AUTOSAR XML (schema 4-0-3)
standard types defined: Boolean, UInt16, UInt32
package /AUTOSAR_Platform/DataConstrs
  range DC_Boolean: raw 0..1
  range DC_UInt16: raw 0..65535
package /PATAC/MSM/ComponentTypes
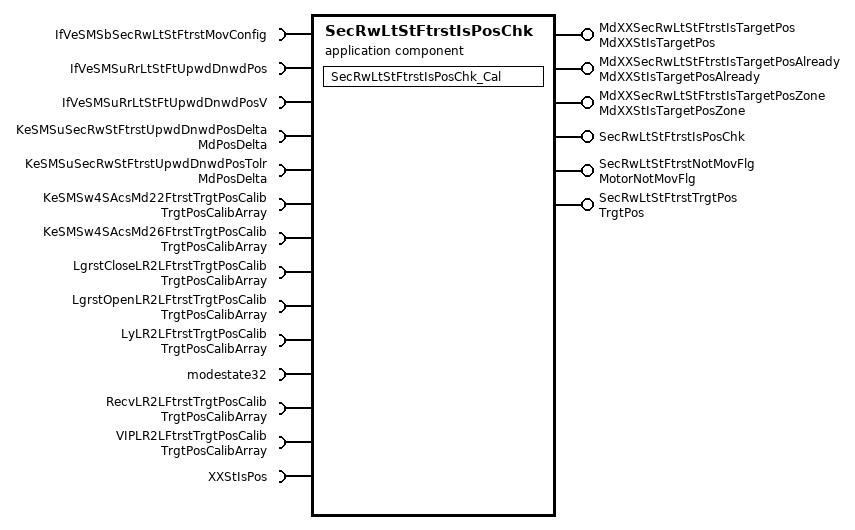
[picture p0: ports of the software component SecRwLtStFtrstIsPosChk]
  application sw component type SecRwLtStFtrstIsPosChk
    6 x provide port:
      MdXXSecRwLtStFtrstIsTargetPos: nonqueued-sender-com-spec=data-element=MdXXStIsTargetPos/Val, provided-interface=MdXXStIsTargetPos
      MdXXSecRwLtStFtrstIsTargetPosAlready: nonqueued-sender-com-spec=data-element=MdXXStIsTargetPosAlready/Val, provided-interface=MdXXStIsTargetPosAlready
      MdXXSecRwLtStFtrstIsTargetPosZone: nonqueued-sender-com-spec=data-element=MdXXStIsTargetPosZone/Val, provided-interface=MdXXStIsTargetPosZone
      SecRwLtStFtrstIsPosChk: server-com-spec{operation=Cal, queue-length=1}, provided-interface=SecRwLtStFtrstIsPosChk
      SecRwLtStFtrstNotMovFlg: nonqueued-sender-com-spec{data-element=MotorNotMovFlg/Val, init-value=0}, provided-interface=MotorNotMovFlg
      SecRwLtStFtrstTrgtPos: nonqueued-sender-com-spec{data-element=TrgtPos/Val, init-value=4095}, provided-interface=TrgtPos
    14 x require port:
      IfVeSMSbSecRwLtStFtrstMovConfig: nonqueued-receiver-com-spec{data-element=IfVeSMSbSecRwLtStFtrstMovConfig/Val, filter=data-filter-type=ALWAYS, init-value=0}, required-interface=IfVeSMSbSecRwLtStFtrstMovConfig
      IfVeSMSuRrLtStFtUpwdDnwdPos: nonqueued-receiver-com-spec{data-element=IfVeSMSuRrLtStFtUpwdDnwdPos/Val, filter=data-filter-type=ALWAYS, init-value=0}, required-interface=IfVeSMSuRrLtStFtUpwdDnwdPos
      IfVeSMSuRrLtStFtUpwdDnwdPosV: nonqueued-receiver-com-spec{data-element=IfVeSMSuRrLtStFtUpwdDnwdPosV/Val, filter=data-filter-type=ALWAYS, init-value=0}, required-interface=IfVeSMSuRrLtStFtUpwdDnwdPosV
      KeSMSuSecRwStFtrstUpwdDnwdPosDelta: parameter-require-com-spec{init-value=150, parameter=Val}, required-interface=MdPosDelta
      KeSMSuSecRwStFtrstUpwdDnwdPosTolr: parameter-require-com-spec{init-value=150, parameter=Val}, required-interface=MdPosDelta
      KeSMSw4SAcsMd22FtrstTrgtPosCalib: nonqueued-receiver-com-spec{data-element=TrgtPosArray, filter=data-filter-type=ALWAYS, init-value=[4095, 4095, 4095]}, required-interface=TrgtPosCalibArray
      KeSMSw4SAcsMd26FtrstTrgtPosCalib: nonqueued-receiver-com-spec{data-element=TrgtPosArray, filter=data-filter-type=ALWAYS, init-value=[4095, 4095, 4095]}, required-interface=TrgtPosCalibArray
      LgrstCloseLR2LFtrstTrgtPosCalib: nonqueued-receiver-com-spec{data-element=TrgtPosArray, filter=data-filter-type=ALWAYS, init-value=[4095, 4095, 4095]}, required-interface=TrgtPosCalibArray
      LgrstOpenLR2LFtrstTrgtPosCalib: nonqueued-receiver-com-spec{data-element=TrgtPosArray, filter=data-filter-type=ALWAYS, init-value=[4095, 4095, 4095]}, required-interface=TrgtPosCalibArray
      LyLR2LFtrstTrgtPosCalib: nonqueued-receiver-com-spec{data-element=TrgtPosArray, filter=data-filter-type=ALWAYS, init-value=[4095, 4095, 4095]}, required-interface=TrgtPosCalibArray
      modestate32: nonqueued-receiver-com-spec{data-element=modestate32/Val, filter=data-filter-type=ALWAYS, init-value=0}, required-interface=modestate32
      RecvLR2LFtrstTrgtPosCalib: nonqueued-receiver-com-spec{data-element=TrgtPosArray, filter=data-filter-type=ALWAYS, init-value=[4095, 4095, 4095]}, required-interface=TrgtPosCalibArray
      VIPLR2LFtrstTrgtPosCalib: nonqueued-receiver-com-spec{data-element=TrgtPosArray, filter=data-filter-type=ALWAYS, init-value=[4095, 4095, 4095]}, required-interface=TrgtPosCalibArray
      XXStIsPos: client-com-spec=Get, required-interface=XXStIsPos
    behavior SecRwLtStFtrstIsPosChk_InternalBehavior
      operation invoked event OIT_SecRwLtStFtrstIsPosChk_Cal_SecRwLtStFtrstIsPosChk_Cal: start-on-event=SecRwLtStFtrstIsPosChk_Cal, operation=SecRwLtStFtrstIsPosChk.Cal
      runnable SecRwLtStFtrstIsPosChk_Cal
        data-receive-point-by-arguments:
          11 x access:
            REC_IfVeSMSbSecRwLtStFtrstMovConfig_Val: accessed-variable=IfVeSMSbSecRwLtStFtrstMovConfig.Val
            REC_IfVeSMSuRrLtStFtUpwdDnwdPos_Val: accessed-variable=IfVeSMSuRrLtStFtUpwdDnwdPos.Val
            REC_IfVeSMSuRrLtStFtUpwdDnwdPosV_Val: accessed-variable=IfVeSMSuRrLtStFtUpwdDnwdPosV.Val
            REC_KeSMSw4SAcsMd22FtrstTrgtPosCalib_TrgtPosArray: accessed-variable=KeSMSw4SAcsMd22FtrstTrgtPosCalib.TrgtPosArray
            REC_KeSMSw4SAcsMd26FtrstTrgtPosCalib_TrgtPosArray: accessed-variable=KeSMSw4SAcsMd26FtrstTrgtPosCalib.TrgtPosArray
            REC_LgrstCloseLR2LFtrstTrgtPosCalib_TrgtPosArray: accessed-variable=LgrstCloseLR2LFtrstTrgtPosCalib.TrgtPosArray
            REC_LgrstOpenLR2LFtrstTrgtPosCalib_TrgtPosArray: accessed-variable=LgrstOpenLR2LFtrstTrgtPosCalib.TrgtPosArray
            REC_LyLR2LFtrstTrgtPosCalib_TrgtPosArray: accessed-variable=LyLR2LFtrstTrgtPosCalib.TrgtPosArray
            REC_modestate32_Val: accessed-variable=modestate32.Val
            REC_RecvLR2LFtrstTrgtPosCalib_TrgtPosArray: accessed-variable=RecvLR2LFtrstTrgtPosCalib.TrgtPosArray
            REC_VIPLR2LFtrstTrgtPosCalib_TrgtPosArray: accessed-variable=VIPLR2LFtrstTrgtPosCalib.TrgtPosArray
        data-send-points:
          5 x access:
            SEND_MdXXSecRwLtStFtrstIsTargetPos_Val: accessed-variable=MdXXSecRwLtStFtrstIsTargetPos.Val
            SEND_MdXXSecRwLtStFtrstIsTargetPosAlready_Val: accessed-variable=MdXXSecRwLtStFtrstIsTargetPosAlready.Val
            SEND_MdXXSecRwLtStFtrstIsTargetPosZone_Val: accessed-variable=MdXXSecRwLtStFtrstIsTargetPosZone.Val
            SEND_SecRwLtStFtrstNotMovFlg_Val: accessed-variable=SecRwLtStFtrstNotMovFlg.Val
            SEND_SecRwLtStFtrstTrgtPos_Val: accessed-variable=SecRwLtStFtrstTrgtPos.Val
        parameter access PA_KeSMSuSecRwStFtrstUpwdDnwdPosDelta_Val: accessed-parameter=KeSMSuSecRwStFtrstUpwdDnwdPosDelta.Val
        parameter access PA_KeSMSuSecRwStFtrstUpwdDnwdPosTolr_Val: accessed-parameter=KeSMSuSecRwStFtrstUpwdDnwdPosTolr.Val
        sync call SC_XXStIsPos_Get: operation=XXStIsPos.Get, timeout=0
  swc implementation SecRwLtStFtrstIsPosChk_Implementation: behavior=SecRwLtStFtrstIsPosChk_InternalBehavior
    code-descriptors:
      code Default: artifact-descriptors=autosar-engineering-object={short-label=Default, category=SWSRC}
package /PATAC/MSM/ModeAdjust/CalPortInterface
  parameter interface MdPosDelta
    parameter data prototype Val: sw-calibration-access=READ-WRITE, type=UInt16
package /PATAC/MSM/ModeAdjust/DataType
  impl type TrgtPosCalibArray: category=ARRAY, sw-calibration-access=READ-ONLY, type-emitter=RTE  # 0:pos 1:max 2:min
    element Element: array-size=3, array-size-semantics=FIXED-SIZE, implementation-data-type=UInt16, invalid-value=0
package /PATAC/MSM/ModeAdjust/PortInterface
  client server interface SecRwLtStFtrstIsPosChk
    operation Cal
  client server interface XXStIsPos
    operation Get
      8 x arg, all with server-argument-impl-policy=USE-ARGUMENT-TYPE:
        PosV: type=DataTypes/Boolean, direction=IN
        Pos: type=UInt16, direction=IN
        CalibArray: type=TrgtPosCalibArray, direction=IN
        Delta: type=UInt16, direction=IN
        Tolr: type=UInt16, direction=IN
        IsPos: type=DataTypes/Boolean, direction=OUT
        IsPosZone: type=DataTypes/Boolean, direction=OUT
        IsPosAlready: type=DataTypes/Boolean, direction=OUT
  7 x sender receiver interface:
    IfVeSMSbSecRwLtStFtrstMovConfig: invalidation-policy{data-element=IfVeSMSbSecRwLtStFtrstMovConfig/Val, handle-invalid=DONT-INVALIDATE}
      data Val: type=Implementation/Boolean
    MdXXStIsTargetPos: invalidation-policy{data-element=MdXXStIsTargetPos/Val, handle-invalid=DONT-INVALIDATE}
      data Val: type=UInt32
    MdXXStIsTargetPosAlready: invalidation-policy{data-element=MdXXStIsTargetPosAlready/Val, handle-invalid=DONT-INVALIDATE}
      data Val: type=UInt32
    MdXXStIsTargetPosZone: invalidation-policy{data-element=MdXXStIsTargetPosZone/Val, handle-invalid=DONT-INVALIDATE}
      data Val: type=UInt32
    modestate32: invalidation-policy{data-element=modestate32/Val, handle-invalid=DONT-INVALIDATE}
      data Val: type=UInt32
    MotorNotMovFlg: invalidation-policy{data-element=MotorNotMovFlg/Val, handle-invalid=DONT-INVALIDATE}
      data Val: type=Implementation/Boolean
    TrgtPosCalibArray: invalidation-policy{data-element=TrgtPosArray, handle-invalid=DONT-INVALIDATE}
      data TrgtPosArray: type=TrgtPosCalibArray  # 0:Pos 1:Max 2:Min
package /PATAC/MSM/PortInterfaces
  sender receiver interface IfVeSMSuRrLtStFtUpwdDnwdPos: invalidation-policy{data-element=IfVeSMSuRrLtStFtUpwdDnwdPos/Val, handle-invalid=DONT-INVALIDATE}
    data Val: type=UInt16
  sender receiver interface IfVeSMSuRrLtStFtUpwdDnwdPosV: invalidation-policy{data-element=IfVeSMSuRrLtStFtUpwdDnwdPosV/Val, handle-invalid=DONT-INVALIDATE}
    data Val: type=Implementation/Boolean
  sender receiver interface TrgtPos: invalidation-policy{data-element=TrgtPos/Val, handle-invalid=DONT-INVALIDATE}
    data Val: type=UInt16
